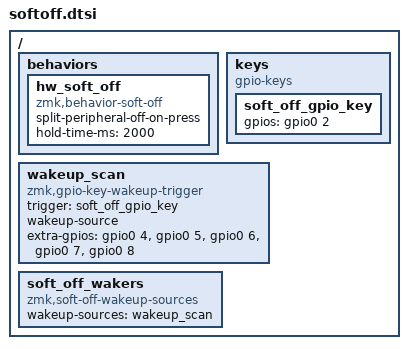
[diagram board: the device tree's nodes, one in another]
/ {
    behaviors {
        hw_soft_off: hw_soft_off {
            compatible = "zmk,behavior-soft-off";
            #binding-cells = <0>;
            split-peripheral-off-on-press; // Turn peripheral off immediately for reliability
            hold-time-ms = <2000>; // Only turn off if the key is held for 2 seconds or longer.
        };
    };
};

/ {
    keys {
        compatible = "gpio-keys";
        soft_off_gpio_key: soft_off_gpio_key {
            gpios = <&gpio0 2 (GPIO_ACTIVE_HIGH | GPIO_PULL_DOWN)>;
        };
    };
};

/ {
    wakeup_scan: wakeup_scan {
        compatible = "zmk,gpio-key-wakeup-trigger";
        trigger = <&soft_off_gpio_key>;
        wakeup-source;
        extra-gpios 
            = <&gpio0 4  GPIO_ACTIVE_HIGH>  // col0 - adjust these based on your cradio shield
            , <&gpio0 5  GPIO_ACTIVE_HIGH>  // col1
            , <&gpio0 6  GPIO_ACTIVE_HIGH>  // col2
            , <&gpio0 7  GPIO_ACTIVE_HIGH>  // col3
            , <&gpio0 8  GPIO_ACTIVE_HIGH>  // col4
            ;
    };
};

/ {
    soft_off_wakers {
        compatible = "zmk,soft-off-wakeup-sources";
        wakeup-sources = <&wakeup_scan>;
    };
};
